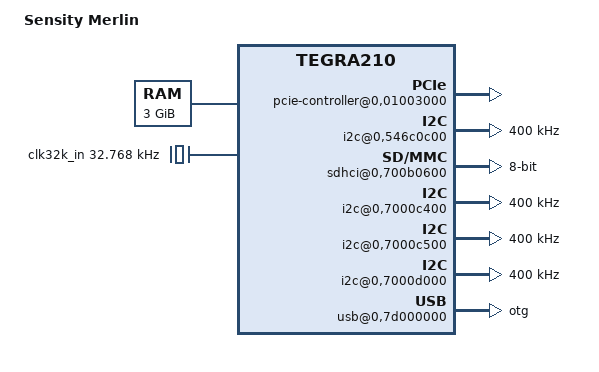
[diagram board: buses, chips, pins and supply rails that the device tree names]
/dts-v1/;

#include "tegra210.dtsi"

/ {
	model = "Sensity Merlin";
	compatible = "sensity,merlin", "nvidia,tegra210";

	signature {
		key-merlin-kernel {
			required = "conf";
			algo = [00];
			rsa,r-squared = <0x9bb34821 0x3e63e543 0x66f88d42 0xe83b846f 0xb44c1847 0x7a7b3b93 0x4ec0ce8d 0x8cdec500 0x8429c630 0x720551b6 0x9fcaf1f0 0x8e1240b 0x95e02da0 0x31b1cb2f 0x8576b1f3 0x8a3e260e 0x4e16a27f 0x79c19872 0x7eee8f55 0x455614f6 0xfceb0d3d 0xdfe39946 0xace46985 0x287bc99c 0x1c1856b1 0x92d7bb57 0xcad30a03 0x82eaeb03 0x97e0b1c8 0x2ca30bf1 0x408e9ee6 0xbb5ba020 0x41095d3 0xc40bd06d 0x8cfe1df5 0xe9330cf0 0xe0b10ec8 0x39d02d5 0x9809dd52 0x4c4874f0 0xef52070c 0xf5a7af2c 0xbfa14a37 0x817028f8 0x2441a20c 0x3daa9f6f 0xacd2534f 0xd71958cb 0x86aa7ee8 0x766c0eae 0x3b3838f1 0x6431a1b7 0x6fb3f912 0x5e7da363 0xc93ab772 0x1e13a430 0xf1c6d850 0xc4de2b84 0x9e9c188f 0xa6bd5ea6 0x4fc85271 0x1031eb44 0x391b9c5b 0x826acc0e>;
			rsa,modulus = <0xc7f6c94d 0x9ef3b2b0 0x27dce40e 0x7cded4b5 0x49eff479 0xfe2cef2a 0xc95049da 0xf9441d2c 0xbfc22896 0xb9f9851f 0x55a04173 0x85c8f268 0xd1c32b85 0x9a168624 0xbe247f2d 0x1bc12afd 0x4778bb2 0x1e1d2681 0xdc84b8b4 0x92150bef 0x3023d398 0xe653e582 0x8a63ca15 0x4befee83 0x81efed2a 0xe42797f6 0xbf426c10 0x4989d72a 0x914a36d2 0x9522eb8b 0xa2f3a889 0x311c26b2 0xb900db81 0x837a33ab 0x215bb69f 0x683bd86 0x4506468 0x33e390fb 0x1a73979f 0x3b544fd6 0xc7f42a41 0x7d47cc08 0xe8b8207a 0xcd94dea3 0xc121b64f 0x26dbe8f4 0xd4d4263a 0xbf53eb05 0x7c715ddd 0xafa14394 0x31f9683e 0x13d44d1d 0xb1750a95 0x6e61db25 0x280b45f2 0x44a5e649 0x98e676fb 0x2407d52f 0xa66c4f45 0x1f10ee6e 0xd7ee3322 0x8cbfa868 0x2d628df3 0xef450d3d>;
			rsa,exponent = <0x0 0x10001>;
			rsa,n0-inverse = <0xe63fcdeb>;
			rsa,num-bits = <0x800>;
			key-name-hint = "merlin-kernel";
		};
	};

	chosen {
		stdout-path = &uarta;
	};

	aliases {
		i2c0 = "/i2c@0,7000d000";
		i2c2 = "/i2c@0,7000c400";
		i2c3 = "/i2c@0,7000c500";
		i2c5 = "/i2c@0,546c0c00";
		sdhci0 = "/sdhci@0,700b0600";
		sdhci1 = "/sdhci@0,700b0000";
		usb0 = "/usb@0,7d000000";
	};

	memory {
		reg = <0x0 0x80000000 0x0 0xc0000000>;
	};

	pcie-controller@0,01003000 {
		status = "okay";

		pci@1,0 {
			status = "okay";
		};

		pci@2,0 {
			status = "disabled";
		};
	};

	i2c@0,546c0c00 {
		status = "okay";
		clock-frequency = <400000>;
	};

	padctl@0,7009f000 {
		pinctrl-0 = <&padctl_default>;
		pinctrl-names = "default";

		padctl_default: pinmux {
			xusb {
				nvidia,lanes = "otg-1", "otg-2";
				nvidia,function = "xusb";
				nvidia,iddq = <0>;
			};

			pcie-x4 {
				nvidia,lanes = "pcie-1", "pcie-2",
					       "pcie-3", "pcie-4";
				nvidia,function = "pcie-x4";
				nvidia,iddq = <0>;
			};

			sata {
				nvidia,lanes = "sata-0";
				nvidia,function = "sata";
				nvidia,iddq = <0>;
			};
		};
	};

	sdhci@0,700b0000 {
		status = "disabled";
		cd-gpios = <&gpio TEGRA_GPIO(Z, 1) GPIO_ACTIVE_LOW>;
		power-gpios = <&gpio TEGRA_GPIO(Z, 3) GPIO_ACTIVE_HIGH>;
		wp-gpios = <&gpio TEGRA_GPIO(Z, 4) GPIO_ACTIVE_LOW>;
		bus-width = <4>;
	};

	sdhci@0,700b0600 {
		status = "okay";
		bus-width = <8>;
	};

	i2c@0,7000c400 {
		status = "okay";
		clock-frequency = <400000>;
	};

	i2c@0,7000c500 {
		status = "okay";
		clock-frequency = <400000>;
	};

	i2c@0,7000d000 {
		status = "okay";
		clock-frequency = <400000>;
	};

	usb@0,7d000000 {
		status = "okay";
		dr_mode = "otg";
		nvidia,vbus-gpio = <&gpio TEGRA_GPIO(CC, 4) GPIO_ACTIVE_HIGH>;
	};

	clocks {
		compatible = "simple-bus";
		#address-cells = <1>;
		#size-cells = <0>;

		clk32k_in: clock@0 {
			compatible = "fixed-clock";
			reg = <0>;
			#clock-cells = <0>;
			clock-frequency = <32768>;
		};
	};
};
